AUTOSAR XML (schema 00050)
package /Components
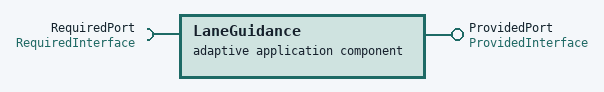
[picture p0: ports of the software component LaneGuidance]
  adaptive application sw component type LaneGuidance
    require port RequiredPort: required-interface=RequiredInterface
      required-com-specs:
        data-element=LeftLaneDistance
        data-element=LeftTurnIndicator
        data-element=RightLaneDistance
        data-element=RightTurnIndicator
        data-element=LeftCarInBlindSpot
        data-element=RightCarInBlindSpot
    provide port ProvidedPort: provided-com-specs=[data-element=LeftHazardIndicator, data-element=RightHazardIndicator], provided-interface=ProvidedInterface
